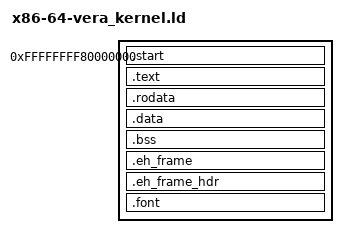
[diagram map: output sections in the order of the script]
ENTRY(_start)

SECTIONS {
    . = 0xffffffff80000000;

    .start : {
        *(.start .start.*)
    }
    .text : {
        *(.text .text.*)
    }
    .rodata : {
        *(.rodata .rodata.*)
    }
    .data : {
        *(.data .data.*)
    }
    .bss : {
        *(.bss .bss.*)
    }
    .eh_frame : {
        *(.eh_frame .eh_frame.*)
    }
    .eh_frame_hdr : {
        *(.eh_frame_hdr .eh_frame_hdr.*)
    }
    .font : {
        *(.font .font.*)
    }
}
